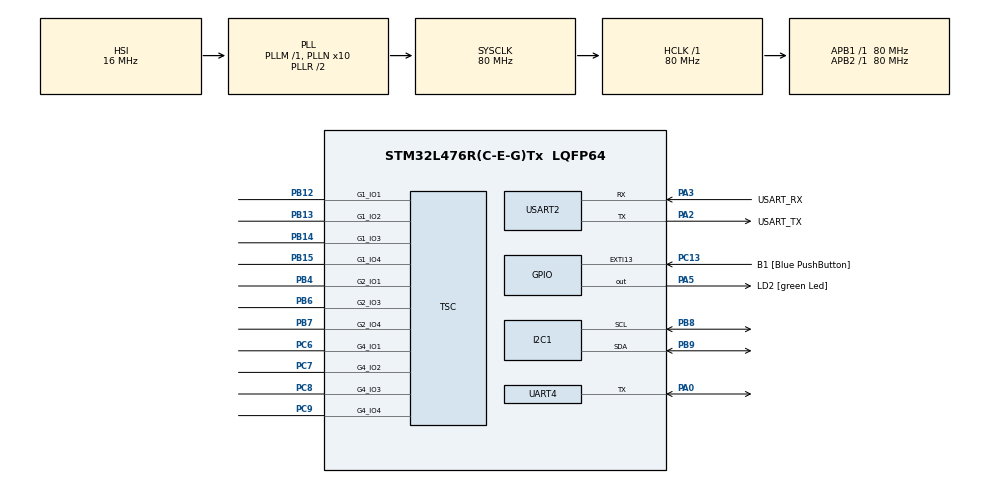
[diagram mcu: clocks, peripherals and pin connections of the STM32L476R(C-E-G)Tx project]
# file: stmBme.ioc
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Mcu.Family=STM32L4
PA2.GPIO_PuPd=GPIO_NOPULL
TOUCHSENSING.IO_TOUCHKEY7=G1_IO3
TOUCHSENSING.IO_TOUCHKEY8=G4_IO3
RCC.CortexFreq_Value=80000000
PH0-OSC_IN\ (PH0).Signal=RCC_OSC_IN
PA3.GPIO_PuPd=GPIO_NOPULL
PA2.GPIO_Speed=GPIO_SPEED_FREQ_VERY_HIGH
TSC.ChannelIOs-G2_IO1=TSC_GROUP2_IO1
PC15-OSC32_OUT\ (PC15).Mode=LSE-External-Oscillator
TSC.ChannelIOs-G2_IO4=TSC_GROUP2_IO4
PC13.GPIO_Label=B1 [Blue PushButton]
PA3.GPIO_Speed=GPIO_SPEED_FREQ_VERY_HIGH
PB15.Signal=TSC_G1_IO4
PB13.Signal=TSC_G1_IO2
RCC.SYSCLKSource=RCC_SYSCLKSOURCE_PLLCLK
ProjectManager.StackSize=0x400
PB3\ (JTDO-TRACESWO).Signal=SYS_JTDO-SWO
PC14-OSC32_IN\ (PC14).Mode=LSE-External-Oscillator
PA14\ (JTCK-SWCLK).Signal=SYS_JTCK-SWCLK
TSC.SamplingIOs-G4_IO4=TSC_GROUP4_IO4
Dma.UART4_TX.0.Direction=DMA_MEMORY_TO_PERIPH
Dma.UART4_TX.0.MemDataAlignment=DMA_MDATAALIGN_BYTE
UART4.BaudRate=31250
RCC.HCLKFreq_Value=80000000
RCC.APB2TimFreq_Value=80000000
PB6.Signal=TSC_G2_IO3
PC7.Signal=TSC_G4_IO2
PB6.Mode=G2_IO3-Sampling
RCC.AHBFreq_Value=80000000
RCC.PREFETCH_ENABLE=1
RCC.HSE_VALUE=8000000
USART2.VirtualMode-Asynchronous=VM_ASYNC
PB14.Mode=G1_IO3-Channel
PA5.GPIO_PuPd=GPIO_NOPULL
PA0.Mode=Half_duplex(single_wire_mode)
PC13.GPIO_PuPd=GPIO_NOPULL
PC9.Mode=G4_IO4-Sampling
PB7.Signal=TSC_G2_IO4
NVIC.DMA2_Channel3_IRQn=true\:0\:0\:false\:false\:true\:false\:true
PA0.Signal=UART4_TX
Mcu.Package=LQFP64
PB9.Signal=I2C1_SDA
PB12.Mode=G1_IO1-Channel
TSC.ChannelIOs-G1_IO2=TSC_GROUP1_IO2
TSC.ChannelIOs-G1_IO3=TSC_GROUP1_IO3
PA2.GPIO_Label=USART_TX
TSC.ChannelIOs-G1_IO1=TSC_GROUP1_IO1
RCC.APB1TimFreq_Value=80000000
PB13.Mode=G1_IO2-Channel
PA13\ (JTMS-SWDIO).Signal=SYS_JTMS-SWDIO
Dma.Request0=UART4_TX
TOUCHSENSING.IO_TOUCHKEY1=G1_IO1
TOUCHSENSING.IO_TOUCHKEY2=G2_IO1
TOUCHSENSING.IO_TOUCHKEY5=G2_IO4
TOUCHSENSING.IO_TOUCHKEY6=G4_IO2
TOUCHSENSING.IO_TOUCHKEY3=G4_IO1
TOUCHSENSING.IO_TOUCHKEY4=G1_IO2
TSC.SamplingIOs-G1_IO4=TSC_GROUP1_IO4
PA3.Signal=USART2_RX
NVIC.UART4_IRQn=true\:0\:0\:false\:false\:true\:true\:true
PA2.GPIO_Mode=GPIO_MODE_AF_PP
RCC.MSI_VALUE=4000000
RCC.PLLSourceVirtual=RCC_PLLSOURCE_HSI
PA14\ (JTCK-SWCLK).Mode=Serial_Wire
Dma.UART4_TX.0.PeriphDataAlignment=DMA_PDATAALIGN_BYTE
PC13.Signal=GPXTI13
PC8.Signal=TSC_G4_IO3
PC6.Signal=TSC_G4_IO1
TSC.ChannelIOs-G4_IO3=TSC_GROUP4_IO3
PC15-OSC32_OUT\ (PC15).Signal=RCC_OSC32_OUT
TSC.ChannelIOs-G4_IO2=TSC_GROUP4_IO2
TSC.ChannelIOs-G4_IO1=TSC_GROUP4_IO1
PA14\ (JTCK-SWCLK).GPIO_Label=TCK
PB3\ (JTDO-TRACESWO).GPIO_Label=SWO
PH1-OSC_OUT\ (PH1).Signal=RCC_OSC_OUT
PA3.Mode=Asynchronous
TSC.SamplingIOs-G2_IO3=TSC_GROUP2_IO3
ProjectManager.TargetToolchain=STM32CubeIDE
PA3.GPIO_Mode=GPIO_MODE_AF_PP
PC6.Mode=G4_IO1-Channel
PB9.Mode=I2C
I2C1.Timing=0x10909CEC
Dma.UART4_TX.0.PeriphInc=DMA_PINC_DISABLE
RCC.USBFreq_Value=64000000
PB14.Signal=TSC_G1_IO3
PA5.Signal=GPIO_Output
Dma.UART4_TX.0.Priority=DMA_PRIORITY_LOW
VP_TOUCHSENSING_VS_TOUCHSENSING.Mode=TouchSensing_Enabled
TOUCHSENSING.TSLPRM_TOTAL_TOUCHKEYS=8
board=NUCLEO-L476RG
RCC.VCOOutputFreq_Value=160000000
PB15.Mode=G1_IO4-Sampling
RCC.APB2Freq_Value=80000000
PA5.GPIO_ModeDefaultOutputPP=GPIO_MODE_OUTPUT_PP
PA13\ (JTMS-SWDIO).GPIO_Label=TMS
Dma.UART4_TX.0.Mode=DMA_NORMAL
TOUCHSENSING.TSLPRM_SENSORS_DATAS=TSLPRM_TOTAL_TOUCHKEYS 3 3 3 2 
RCC.ADCFreq_Value=64000000
PB4\ (NJTRST).Mode=G2_IO1-Channel
Mcu.Name=STM32L476R(C-E-G)Tx
PA2.Signal=USART2_TX
PC8.Mode=G4_IO3-Channel
PA13\ (JTMS-SWDIO).Mode=Serial_Wire
RCC.SYSCLKFreq_VALUE=80000000
PA5.GPIO_Label=LD2 [green Led]
PC13.GPIO_ModeDefaultEXTI=GPIO_MODE_IT_FALLING
PC14-OSC32_IN\ (PC14).Signal=RCC_OSC32_IN
Dma.UART4_TX.0.MemInc=DMA_MINC_ENABLE
PB7.Mode=G2_IO4-Channel
ProjectManager.HeapSize=0x200
RCC.HSI_VALUE=16000000
PA5.GPIO_Speed=GPIO_SPEED_FREQ_LOW
NVIC.PriorityGroup=NVIC_PRIORITYGROUP_4
RCC.PLLN=10
PB8.Mode=I2C
PA2.Mode=Asynchronous
PB8.Signal=I2C1_SCL
PC9.Signal=TSC_G4_IO4
PC7.Mode=G4_IO2-Channel
RCC.APB1Freq_Value=80000000
PB12.Signal=TSC_G1_IO1
PA3.GPIO_Label=USART_RX
Dma.UART4_TX.0.Instance=DMA2_Channel3
PB4\ (NJTRST).Signal=TSC_G2_IO1

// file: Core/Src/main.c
/* USER CODE BEGIN Header */
/**
  ******************************************************************************
  * @file           : main.c
  * @brief          : Main program body
  ******************************************************************************
  * @attention
  *
  * <h2><center>&copy; Copyright (c) 2021 STMicroelectronics.
  * All rights reserved.</center></h2>
  *
  * This software component is licensed by ST under BSD 3-Clause license,
  * the "License"; You may not use this file except in compliance with the
  * License. You may obtain a copy of the License at:
  *                        opensource.org/licenses/BSD-3-Clause
  *
  ******************************************************************************
  */
/* USER CODE END Header */
#include "main.h"
#include "touchsensing.h"

/* USER CODE BEGIN Includes */
#include "userMain.h"
/* USER CODE END Includes */

I2C_HandleTypeDef hi2c1;

TSC_HandleTypeDef htsc;

UART_HandleTypeDef huart4;
UART_HandleTypeDef huart2;
DMA_HandleTypeDef hdma_uart4_tx;

void SystemClock_Config(void);
static void MX_GPIO_Init(void);
static void MX_DMA_Init(void);
static void MX_USART2_UART_Init(void);
static void MX_I2C1_Init(void);
static void MX_UART4_Init(void);
static void MX_TSC_Init(void);

int main(void)
{

  /* MCU Configuration--------------------------------------------------------*/

  /* Reset of all peripherals, Initializes the Flash interface and the Systick. */
  HAL_Init();

  /* Configure the system clock */
  SystemClock_Config();

  /* Initialize all configured peripherals */
  MX_GPIO_Init();
  MX_DMA_Init();
  MX_USART2_UART_Init();
  MX_I2C1_Init();
  MX_UART4_Init();
  MX_TSC_Init();
  MX_TOUCHSENSING_Init();
  /* USER CODE BEGIN 2 */
  userMain();

  /* USER CODE END 2 */

  /* Infinite loop */
  while (1)
  {

  }
}

void SystemClock_Config(void)
{
  RCC_OscInitTypeDef RCC_OscInitStruct = {0};
  RCC_ClkInitTypeDef RCC_ClkInitStruct = {0};
  RCC_PeriphCLKInitTypeDef PeriphClkInit = {0};

  /** Initializes the RCC Oscillators according to the specified parameters
  * in the RCC_OscInitTypeDef structure.
  */
  RCC_OscInitStruct.OscillatorType = RCC_OSCILLATORTYPE_HSI;
  RCC_OscInitStruct.HSIState = RCC_HSI_ON;
  RCC_OscInitStruct.HSICalibrationValue = RCC_HSICALIBRATION_DEFAULT;
  RCC_OscInitStruct.PLL.PLLState = RCC_PLL_ON;
  RCC_OscInitStruct.PLL.PLLSource = RCC_PLLSOURCE_HSI;
  RCC_OscInitStruct.PLL.PLLM = 1;
  RCC_OscInitStruct.PLL.PLLN = 10;
  RCC_OscInitStruct.PLL.PLLP = RCC_PLLP_DIV7;
  RCC_OscInitStruct.PLL.PLLQ = RCC_PLLQ_DIV2;
  RCC_OscInitStruct.PLL.PLLR = RCC_PLLR_DIV2;
  if (HAL_RCC_OscConfig(&RCC_OscInitStruct) != HAL_OK)
  {
    Error_Handler();
  }
  /** Initializes the CPU, AHB and APB buses clocks
  */
  RCC_ClkInitStruct.ClockType = RCC_CLOCKTYPE_HCLK|RCC_CLOCKTYPE_SYSCLK
                              |RCC_CLOCKTYPE_PCLK1|RCC_CLOCKTYPE_PCLK2;
  RCC_ClkInitStruct.SYSCLKSource = RCC_SYSCLKSOURCE_PLLCLK;
  RCC_ClkInitStruct.AHBCLKDivider = RCC_SYSCLK_DIV1;
  RCC_ClkInitStruct.APB1CLKDivider = RCC_HCLK_DIV1;
  RCC_ClkInitStruct.APB2CLKDivider = RCC_HCLK_DIV1;

  if (HAL_RCC_ClockConfig(&RCC_ClkInitStruct, FLASH_LATENCY_4) != HAL_OK)
  {
    Error_Handler();
  }
  PeriphClkInit.PeriphClockSelection = RCC_PERIPHCLK_USART2|RCC_PERIPHCLK_UART4
                              |RCC_PERIPHCLK_I2C1;
  PeriphClkInit.Usart2ClockSelection = RCC_USART2CLKSOURCE_PCLK1;
  PeriphClkInit.Uart4ClockSelection = RCC_UART4CLKSOURCE_PCLK1;
  PeriphClkInit.I2c1ClockSelection = RCC_I2C1CLKSOURCE_PCLK1;
  if (HAL_RCCEx_PeriphCLKConfig(&PeriphClkInit) != HAL_OK)
  {
    Error_Handler();
  }
  /** Configure the main internal regulator output voltage
  */
  if (HAL_PWREx_ControlVoltageScaling(PWR_REGULATOR_VOLTAGE_SCALE1) != HAL_OK)
  {
    Error_Handler();
  }
}

static void MX_I2C1_Init(void)
{

  hi2c1.Instance = I2C1;
  hi2c1.Init.Timing = 0x10909CEC;
  hi2c1.Init.OwnAddress1 = 0;
  hi2c1.Init.AddressingMode = I2C_ADDRESSINGMODE_7BIT;
  hi2c1.Init.DualAddressMode = I2C_DUALADDRESS_DISABLE;
  hi2c1.Init.OwnAddress2 = 0;
  hi2c1.Init.OwnAddress2Masks = I2C_OA2_NOMASK;
  hi2c1.Init.GeneralCallMode = I2C_GENERALCALL_DISABLE;
  hi2c1.Init.NoStretchMode = I2C_NOSTRETCH_DISABLE;
  if (HAL_I2C_Init(&hi2c1) != HAL_OK)
  {
    Error_Handler();
  }
  /** Configure Analogue filter
  */
  if (HAL_I2CEx_ConfigAnalogFilter(&hi2c1, I2C_ANALOGFILTER_ENABLE) != HAL_OK)
  {
    Error_Handler();
  }
  /** Configure Digital filter
  */
  if (HAL_I2CEx_ConfigDigitalFilter(&hi2c1, 0) != HAL_OK)
  {
    Error_Handler();
  }

}

static void MX_TSC_Init(void)
{

  /** Configure the TSC peripheral
  */
  htsc.Instance = TSC;
  htsc.Init.CTPulseHighLength = TSC_CTPH_2CYCLES;
  htsc.Init.CTPulseLowLength = TSC_CTPL_2CYCLES;
  htsc.Init.SpreadSpectrum = DISABLE;
  htsc.Init.SpreadSpectrumDeviation = 1;
  htsc.Init.SpreadSpectrumPrescaler = TSC_SS_PRESC_DIV1;
  htsc.Init.PulseGeneratorPrescaler = TSC_PG_PRESC_DIV4;
  htsc.Init.MaxCountValue = TSC_MCV_8191;
  htsc.Init.IODefaultMode = TSC_IODEF_OUT_PP_LOW;
  htsc.Init.SynchroPinPolarity = TSC_SYNC_POLARITY_FALLING;
  htsc.Init.AcquisitionMode = TSC_ACQ_MODE_NORMAL;
  htsc.Init.MaxCountInterrupt = DISABLE;
  htsc.Init.ChannelIOs = TSC_GROUP1_IO1|TSC_GROUP1_IO2|TSC_GROUP1_IO3|TSC_GROUP2_IO1
                    |TSC_GROUP2_IO4|TSC_GROUP4_IO1|TSC_GROUP4_IO2|TSC_GROUP4_IO3;
  htsc.Init.ShieldIOs = 0;
  htsc.Init.SamplingIOs = TSC_GROUP1_IO4|TSC_GROUP2_IO3|TSC_GROUP4_IO4;
  if (HAL_TSC_Init(&htsc) != HAL_OK)
  {
    Error_Handler();
  }

}

static void MX_UART4_Init(void)
{

  huart4.Instance = UART4;
  huart4.Init.BaudRate = 31250;
  huart4.Init.WordLength = UART_WORDLENGTH_8B;
  huart4.Init.StopBits = UART_STOPBITS_1;
  huart4.Init.Parity = UART_PARITY_NONE;
  huart4.Init.Mode = UART_MODE_TX_RX;
  huart4.Init.HwFlowCtl = UART_HWCONTROL_NONE;
  huart4.Init.OverSampling = UART_OVERSAMPLING_16;
  huart4.Init.OneBitSampling = UART_ONE_BIT_SAMPLE_DISABLE;
  huart4.AdvancedInit.AdvFeatureInit = UART_ADVFEATURE_NO_INIT;
  if (HAL_HalfDuplex_Init(&huart4) != HAL_OK)
  {
    Error_Handler();
  }

}

static void MX_USART2_UART_Init(void)
{

  huart2.Instance = USART2;
  huart2.Init.BaudRate = 115200;
  huart2.Init.WordLength = UART_WORDLENGTH_8B;
  huart2.Init.StopBits = UART_STOPBITS_1;
  huart2.Init.Parity = UART_PARITY_NONE;
  huart2.Init.Mode = UART_MODE_TX_RX;
  huart2.Init.HwFlowCtl = UART_HWCONTROL_NONE;
  huart2.Init.OverSampling = UART_OVERSAMPLING_16;
  huart2.Init.OneBitSampling = UART_ONE_BIT_SAMPLE_DISABLE;
  huart2.AdvancedInit.AdvFeatureInit = UART_ADVFEATURE_NO_INIT;
  if (HAL_UART_Init(&huart2) != HAL_OK)
  {
    Error_Handler();
  }

}

static void MX_DMA_Init(void)
{

  /* DMA controller clock enable */
  __HAL_RCC_DMA2_CLK_ENABLE();

  /* DMA interrupt init */
  /* DMA2_Channel3_IRQn interrupt configuration */
  HAL_NVIC_SetPriority(DMA2_Channel3_IRQn, 0, 0);
  HAL_NVIC_EnableIRQ(DMA2_Channel3_IRQn);

}

static void MX_GPIO_Init(void)
{
  GPIO_InitTypeDef GPIO_InitStruct = {0};

  /* GPIO Ports Clock Enable */
  __HAL_RCC_GPIOC_CLK_ENABLE();
  __HAL_RCC_GPIOH_CLK_ENABLE();
  __HAL_RCC_GPIOA_CLK_ENABLE();
  __HAL_RCC_GPIOB_CLK_ENABLE();

  /*Configure GPIO pin Output Level */
  HAL_GPIO_WritePin(LD2_GPIO_Port, LD2_Pin, GPIO_PIN_RESET);

  /*Configure GPIO pin : B1_Pin */
  GPIO_InitStruct.Pin = B1_Pin;
  GPIO_InitStruct.Mode = GPIO_MODE_IT_FALLING;
  GPIO_InitStruct.Pull = GPIO_NOPULL;
  HAL_GPIO_Init(B1_GPIO_Port, &GPIO_InitStruct);

  /*Configure GPIO pin : LD2_Pin */
  GPIO_InitStruct.Pin = LD2_Pin;
  GPIO_InitStruct.Mode = GPIO_MODE_OUTPUT_PP;
  GPIO_InitStruct.Pull = GPIO_NOPULL;
  GPIO_InitStruct.Speed = GPIO_SPEED_FREQ_LOW;
  HAL_GPIO_Init(LD2_GPIO_Port, &GPIO_InitStruct);

}

void Error_Handler(void)
{
  __disable_irq();
  while (1)
  {
  }
}

/************************ (C) COPYRIGHT STMicroelectronics *****END OF FILE****/
